AUTOSAR XML (schema 00049)
package /AdaptiveApplicationSwComponentTypes
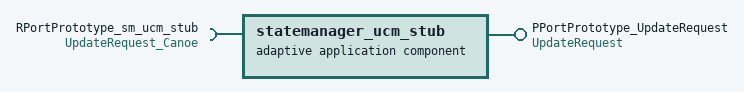
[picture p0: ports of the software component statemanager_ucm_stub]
  adaptive application sw component type statemanager_ucm_stub
    require port RPortPrototype_sm_ucm_stub: required-interface=UpdateRequest_Canoe
    provide port PPortPrototype_UpdateRequest: provided-interface=UpdateRequest
